# CY8C5287AXI_LP095 register map
File version: 0.1
CY8C52LP
Registers are 8-bit, read-write, no defined reset value unless marked. A register's access mark holds for its fields unless they carry their own. Offsets are from the block's base; lines under a group give offsets from that group; [hi:lo] are bit positions; {n}, {i} and the like mark numbered series; 'fields as' and 'values as' point back to an identical list; <NAME> marks a mode.

## Memory map
0x00000000 I2C
0x00000000 I2C_1
0x00000000 CapSense
0x00000000 CapSense_IdacCH0
0x00000000 CapSense_CompCH0
0x00000000 UART1 — UART
0x00000000 PWM_1

## I2C
Base 0x00000000
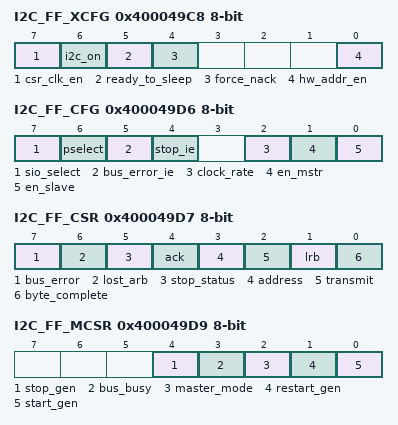
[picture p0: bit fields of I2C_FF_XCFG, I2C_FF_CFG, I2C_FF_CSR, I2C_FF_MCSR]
0x400049C8 I2C_FF_XCFG — Extended Configuration Register: I2C_XCFG
  [7] csr_clk_en, [6] i2c_on, [5] ready_to_sleep ro, [4] force_nack, [0] hw_addr_en
0x400049CA I2C_FF_ADDR — Slave Adddress Register: I2C_ADR
  [6:0] slave_address — This register holds the slave's 7-bit address.
0x400049D6 I2C_FF_CFG — Configuration Register: I2C_CFG
  [7] sio_select, [6] pselect, [5] bus_error_ie, [4] stop_ie, [2] clock_rate, [1] en_mstr, [0] en_slave
0x400049D7 I2C_FF_CSR — Control and Status Register: I2C_CSR
  [7] bus_error, [6] lost_arb, [5] stop_status, [4] ack, [3] address, [2] transmit, [1] lrb, [0] byte_complete
0x400049D8 I2C_FF_DATA — Data Register: I2C_D
  [7:0] data — This register provides read/write access to the Shift register.
0x400049D9 I2C_FF_MCSR — Master Control and Status Register: I2C_MCSR
  [4] stop_gen, [3] bus_busy ro, [2] master_mode ro, [1] restart_gen, [0] start_gen
0x400049DB I2C_FF__CLK_DIV1 — Divider of BUS_CLK low part: I2C_CLK_DIV1
  [7:0] Div
0x400049DC I2C_FF__CLK_DIV2 — Divider high part: I2C_CLK_DIV1
  [1:0] Div
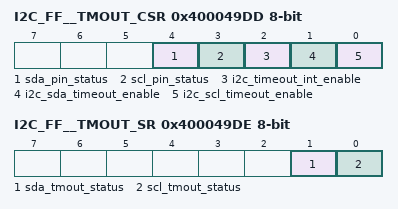
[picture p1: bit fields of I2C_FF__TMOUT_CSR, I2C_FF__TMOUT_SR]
0x400049DD I2C_FF__TMOUT_CSR — Extended Configuration Register: I2C_TMOUT_CSR
  [4] sda_pin_status, [3] scl_pin_status, [2] i2c_timeout_int_enable ro, [1] i2c_sda_timeout_enable, [0] i2c_scl_timeout_enable
0x400049DE I2C_FF__TMOUT_SR — Extended Configuration Register: I2C_TMOUT_SR
  [1] sda_tmout_status, [0] scl_tmout_status
0x400049DF I2C_FF__TMOUT_CFG0 — Extended Configuration Register: TMOUT_CFG0
  [7:0] timeout_period_lowbyte
0x400049E0 I2C_FF__TMOUT_CFG1 — Extended Configuration Register: TMOUT_CFG1
  [3:0] timeout_period_highnibble

## I2C_1
Base 0x00000000
0x40006400 I2C_1_UDB_MSTR_DATA — Data
  [7:0] data — This register provides read/write access to the Shift register.
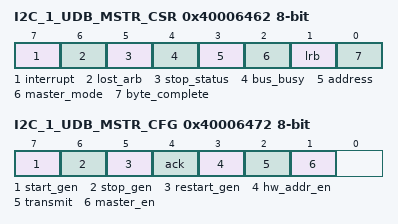
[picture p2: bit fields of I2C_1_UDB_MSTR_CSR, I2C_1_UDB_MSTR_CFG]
0x40006462 I2C_1_UDB_MSTR_CSR — Status Register
  [7] interrupt ro — Interrupt bit
  [6] lost_arb ro
  [5] stop_status
  [4] bus_busy ro
  [3] address ro
  [2] master_mode ro
  [1] lrb ro
  [0] byte_complete ro
0x40006472 I2C_1_UDB_MSTR_CFG — Configuration Register
  [7] start_gen, [6] stop_gen, [5] restart_gen, [4] ack, [3] hw_addr_en, [2] transmit, [1] master_en
0x40006482 I2C_1_UDB_MSTR_INT_MASK — Interrupt Mask

## CapSense
Base 0x00000000
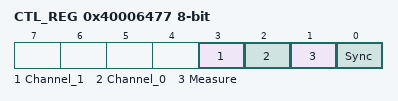
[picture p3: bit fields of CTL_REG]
0x40006477 CTL_REG — CapSense Control Register
  [3] Channel_1 ro — Channel 1 Enable
    0=Disabled (Channel 1 scanning is disabled); 1=Enabled (Channel 1 scanning is enabled)
  [2] Channel_0 ro — Channel 0 Enable
    0=Disabled (Channel 0 scanning is disabled); 1=Enabled (Channel 0 scanning is enabled)
  [1] Measure ro — Measurement Enable
    0=Disabled (Capacitance measurement is disabled); 1=Enabled (Capacitance measurement is enabled)
  [0] Sync ro — Reset Digital and Pre-Charge Clocks
    0=Disabled (Clocks are in the reset state); 1=Enabled (Clocks are enabled)
0x40006493 ScanSpeed_CTL_REG — CapSense Clock Prescaler Control Register
  [3] Counter ro — Clock Prescaler Enable
    0=Disabled (Prescaler counter is disabled); 1=Enabled (Prescaler counter is enabled)

## CapSense_IdacCH0
Base 0x00000000
0x400043A8 IDAC8_PM_ACT_CFG — Active Power Mode Configuration Register 8
  [3:0] en_dac — Enable DAC block(s). Populated subsystems are counted from the LSB.
0x400043B8 IDAC8_PM_STBY_CFG — Standby Power Mode Configuration Register 8
  fields as IDAC8_PM_ACT_CFG
0x40004608 IDAC8_TR
  [7:0] tr — 8 Calibration bits
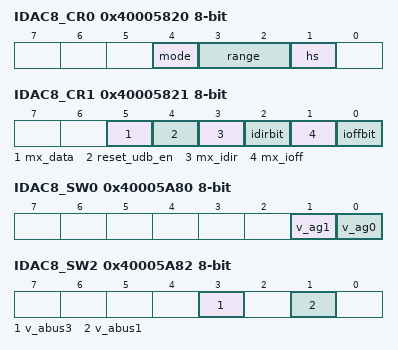
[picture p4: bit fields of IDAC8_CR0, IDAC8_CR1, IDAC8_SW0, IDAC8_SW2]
0x40005820 IDAC8_CR0 — DAC Block Control Register 0
  [4] mode ro — Mode Bit
    0=DAC_MODE_V (voltage DAC); 1=DAC_MODE_I (current DAC)
  [3:2] range — Ranges for mode=0 (VDAC) and mode=1 (IDAC)
    0=DAC_RANGE_0 (x0=0V to 4*vref (1.024V); 0 to 31.875uA); 1=DAC_RANGE_1 (x1=0V to 16*vref (4.096V); 0 to 255uA); 2=DAC_RANGE_2 (x0=0V to 4*vref (1.024V); 0 to 2.040mA); 3=DAC_RANGE_3 (x1=0V to 16*vref (4.096V); not used)
  [1] hs — High Speed Bit
    0=DAC_HS_LOWPOWER (regular (low power)); 1=DAC_HS_HIGHSPEED (high speed (higher power))
0x40005821 IDAC8_CR1 — DAC Block Control Register 1
  [5] mx_data — Select DATA source
    0=MX_DATA_REG (Select register source); 1=MX_DATA_UDB (Select UDB source)
  [4] reset_udb_en — DAC reset enable
    0=RESET_UDB_EN_DISABLE (Disable DAC Reset Source from UDB); 1=RESET_UDB_EN_ENABLE (Enable DAC Reset Source from UDB)
  [3] mx_idir — Mux selection for DAC current direction control
    0=MX_IDIR_REG (Register source idirbit selected); 1=MX_IDIR_UDB (UDB ictrl selected)
  [2] idirbit — register source for DAC current direction
  [1] mx_ioff — Mux selection for DAC current off control
    0=MX_IOFF_REG (Register source ioffbit selected); 1=MX_IOFF_UDB (UDB ictrl selected)
  [0] ioffbit — register source for DAC current off
0x40005A80 IDAC8_SW0 — DAC Analog Routing Register 0
  [1] v_ag1 — Connect voltage output to analog global of same side
    0=AG_NC (not connected); 1=AG_CONNECTED (Connect to Analog Global)
  [0] v_ag0 — Connect voltage output to analog global of same side
    values as v_ag1
0x40005A82 IDAC8_SW2 — DAC Analog Routing Register 2
  [3] v_abus3 — Connect voltage output to analog (local) bus of the same side
    0=ABUS_NC (not connected); 1=ABUS_CONNECTED (Connect to Analog (local) Bus)
  [1] v_abus1 — Connect voltage output to analog (local) bus of the same side
    values as v_abus3
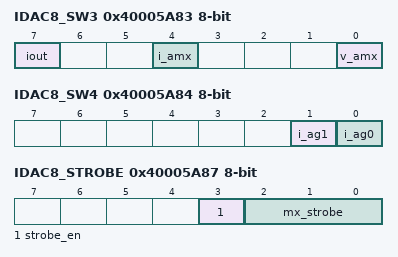
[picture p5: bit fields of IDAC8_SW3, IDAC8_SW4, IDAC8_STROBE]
0x40005A83 IDAC8_SW3 — DAC Analog Routing Register 3
  [7] iout — Connect current output to pad
    0=IOUT_NC (not connected); 1=IOUT_CONNECT (Connect to pad)
  [4] i_amx — Connect current output to Analog Mux Bus
    0=AMX_NC (not connected); 1=AMX_CONNECTED (Connect to AMUXBUS)
  [0] v_amx — Connect voltage output to Analog Mux Bus
    values as i_amx
0x40005A84 IDAC8_SW4 — DAC Analog Routing Register 4
  [1] i_ag1 — Connect current output to analog global of same side
    values as IDAC8_SW0.v_ag1
  [0] i_ag0 — Connect current output to analog global of same side
    values as IDAC8_SW0.v_ag1
0x40005A87 IDAC8_STROBE — DAC Strobe Register
  [3] strobe_en — Strobe gating control
    0=disable strobe; 1=enable strobe
  [2:0] mx_strobe — Strobe source selection
    0=MX_STROBE_BUSWRITE (Select bus write strobe source); 1=MX_STROBE_UDB_SRC (Select UDB strobe source); 2=MX_STROBE_NC_2 (NC); 3=MX_STROBE_NC_3 (NC); {v}=MX_STROBE_CLK_A{v-4}_DIG (Select clk_a{v-4}_dig) (v=4..7)
0x40005B80 IDAC8_D — DAC Data Register
  [7:0] data — 8 DAC Data bits
